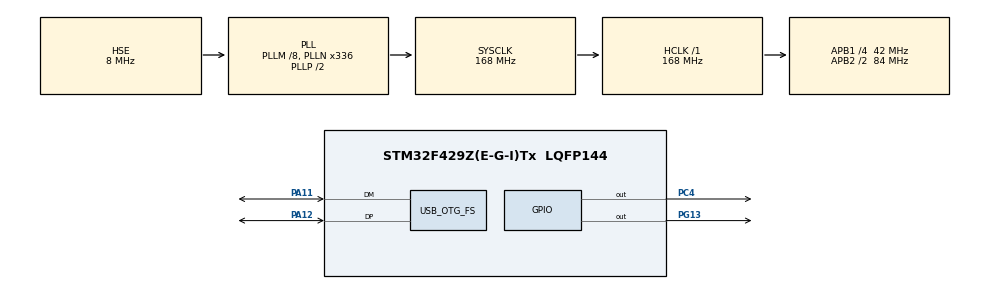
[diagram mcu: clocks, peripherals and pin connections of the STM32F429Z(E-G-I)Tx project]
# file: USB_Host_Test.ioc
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Mcu.Family=STM32F4
Mcu.Name=STM32F429Z(E-G-I)Tx
Mcu.Package=LQFP144
NVIC.OTG_FS_IRQn=true\:0\:0\:false
NVIC.PriorityGroup=NVIC_PRIORITYGROUP_4
PA11.GPIO_Mode=GPIO_MODE_AF_PP
PA11.GPIO_PuPd=GPIO_NOPULL
PA11.GPIO_Speed=GPIO_SPEED_HIGH
PA11.Mode=Host_Only
PA11.Signal=USB_OTG_FS_DM
PA12.GPIO_Mode=GPIO_MODE_AF_PP
PA12.GPIO_PuPd=GPIO_NOPULL
PA12.GPIO_Speed=GPIO_SPEED_HIGH
PA12.Mode=Host_Only
PA12.Signal=USB_OTG_FS_DP
PC4.Signal=GPIO_Output
PG13.Signal=GPIO_Output
PH0/OSC_IN.Mode=HSE-External-Oscillator
PH0/OSC_IN.Signal=RCC_OSC_IN
PH1/OSC_OUT.Mode=HSE-External-Oscillator
PH1/OSC_OUT.Signal=RCC_OSC_OUT
ProjectManager.TargetToolchain=MDK-ARM 4.73
RCC.48MHZClocksFreq_Value=48000000
RCC.AHBFreq_Value=168000000
RCC.APB1CLKDivider=RCC_HCLK_DIV4
RCC.APB1Freq_Value=42000000
RCC.APB1TimFreq_Value=84000000
RCC.APB2CLKDivider=RCC_HCLK_DIV2
RCC.APB2Freq_Value=84000000
RCC.APB2TimFreq_Value=168000000
RCC.CortexFreq_Value=168000000
RCC.HCLKFreq_Value=168000000
RCC.HSE_VALUE=8000000
RCC.HSI_VALUE=16000000
RCC.LSE_VALUE=32768
RCC.PLLM=8
RCC.PLLN=336
RCC.PLLQ=7
RCC.SYSCLKFreq_VALUE=168000000
RCC.SYSCLKSource=RCC_SYSCLKSOURCE_PLLCLK
RCC.VCOOutputFreq_Value=336000000
USB_HOST.BSP.number=1
USB_HOST.USBH_DEBUG_LEVEL-ALL_Classes_FS=3
USB_HOST.USBH_HandleTypeDef-ALL_Classes_FS=hUsbHostFS
USB_HOST.USBH_MAX_DATA_BUFFER-ALL_Classes_FS=4096
USB_HOST.USBH_MAX_NUM_ENDPOINTS-ALL_Classes_FS=1
USB_HOST.USBH_MAX_NUM_SUPPORTED_CLASS-ALL_Classes_FS=6
USB_HOST.USBH_MAX_SIZE_CONFIGURATION-ALL_Classes_FS=512
USB_HOST.VirtualModeFS=All_Classes
USB_HOST.VirtualModeFS-ALL_Classes_FS=All_Classes
USB_HOST0.BSP.i2caddr=0
USB_HOST0.BSP.i2creg=0
USB_HOST0.BSP.instance=PC4
USB_HOST0.BSP.ip=GPIO
USB_HOST0.BSP.mode=Output
USB_HOST0.BSP.name=Drive_VBUS_FS
USB_OTG_FS.phy_itface=HCD_PHY_EMBEDDED
USB_OTG_FS.phy_itface-Host_Only=HCD_PHY_EMBEDDED
VP_USB_HOST_VS_USB_HOST_ALL_CLASS_FS.Mode=ALL_Classes_FS
board=USB_Host_Test

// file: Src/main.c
/**
  ******************************************************************************
  * File Name          : main.c
  * Description        : Main program body
  ******************************************************************************
  *
  * COPYRIGHT(c) 2015 STMicroelectronics
  *
  * Redistribution and use in source and binary forms, with or without modification,
  * are permitted provided that the following conditions are met:
  *   1. Redistributions of source code must retain the above copyright notice,
  *      this list of conditions and the following disclaimer.
  *   2. Redistributions in binary form must reproduce the above copyright notice,
  *      this list of conditions and the following disclaimer in the documentation
  *      and/or other materials provided with the distribution.
  *   3. Neither the name of STMicroelectronics nor the names of its contributors
  *      may be used to endorse or promote products derived from this software
  *      without specific prior written permission.
  *
  * THIS SOFTWARE IS PROVIDED BY THE COPYRIGHT HOLDERS AND CONTRIBUTORS "AS IS"
  * AND ANY EXPRESS OR IMPLIED WARRANTIES, INCLUDING, BUT NOT LIMITED TO, THE
  * IMPLIED WARRANTIES OF MERCHANTABILITY AND FITNESS FOR A PARTICULAR PURPOSE ARE
  * DISCLAIMED. IN NO EVENT SHALL THE COPYRIGHT HOLDER OR CONTRIBUTORS BE LIABLE
  * FOR ANY DIRECT, INDIRECT, INCIDENTAL, SPECIAL, EXEMPLARY, OR CONSEQUENTIAL
  * DAMAGES (INCLUDING, BUT NOT LIMITED TO, PROCUREMENT OF SUBSTITUTE GOODS OR
  * SERVICES; LOSS OF USE, DATA, OR PROFITS; OR BUSINESS INTERRUPTION) HOWEVER
  * CAUSED AND ON ANY THEORY OF LIABILITY, WHETHER IN CONTRACT, STRICT LIABILITY,
  * OR TORT (INCLUDING NEGLIGENCE OR OTHERWISE) ARISING IN ANY WAY OUT OF THE USE
  * OF THIS SOFTWARE, EVEN IF ADVISED OF THE POSSIBILITY OF SUCH DAMAGE.
  *
  ******************************************************************************
  */
#include "stm32f4xx_hal.h"
#include "usb_host.h"

/* USER CODE BEGIN Includes */
#include <stdio.h>

struct __FILE { int handle; /* Add whatever needed */ };
FILE __stdout;
FILE __stdin;

/* USER CODE END Includes */

/* USER CODE BEGIN PV */
/* Private variables ---------------------------------------------------------*/

/* USER CODE END PV */

void SystemClock_Config(void);
static void MX_GPIO_Init(void);
void MX_USB_HOST_Process(void);

/* USER CODE BEGIN PFP */
/* Private function prototypes -----------------------------------------------*/

/* USER CODE END PFP */

int main(void)
{

  /* MCU Configuration----------------------------------------------------------*/

  /* Reset of all peripherals, Initializes the Flash interface and the Systick. */
  HAL_Init();

  /* Configure the system clock */
  SystemClock_Config();

  /* Initialize all configured peripherals */
  MX_GPIO_Init();
  MX_USB_HOST_Init();
	printf("TEST");

  /* Infinite loop */
  while (1)
  {
    MX_USB_HOST_Process();

  }

}

/** System Clock Configuration
*/
void SystemClock_Config(void)
{

  RCC_OscInitTypeDef RCC_OscInitStruct;
  RCC_ClkInitTypeDef RCC_ClkInitStruct;

  __PWR_CLK_ENABLE();

  __HAL_PWR_VOLTAGESCALING_CONFIG(PWR_REGULATOR_VOLTAGE_SCALE1);

  RCC_OscInitStruct.OscillatorType = RCC_OSCILLATORTYPE_HSE;
  RCC_OscInitStruct.HSEState = RCC_HSE_ON;
  RCC_OscInitStruct.PLL.PLLState = RCC_PLL_ON;
  RCC_OscInitStruct.PLL.PLLSource = RCC_PLLSOURCE_HSE;
  RCC_OscInitStruct.PLL.PLLM = 8;
  RCC_OscInitStruct.PLL.PLLN = 336;
  RCC_OscInitStruct.PLL.PLLP = RCC_PLLP_DIV2;
  RCC_OscInitStruct.PLL.PLLQ = 7;
  HAL_RCC_OscConfig(&RCC_OscInitStruct);

  RCC_ClkInitStruct.ClockType = RCC_CLOCKTYPE_SYSCLK|RCC_CLOCKTYPE_PCLK1
                              |RCC_CLOCKTYPE_PCLK2;
  RCC_ClkInitStruct.SYSCLKSource = RCC_SYSCLKSOURCE_PLLCLK;
  RCC_ClkInitStruct.AHBCLKDivider = RCC_SYSCLK_DIV1;
  RCC_ClkInitStruct.APB1CLKDivider = RCC_HCLK_DIV4;
  RCC_ClkInitStruct.APB2CLKDivider = RCC_HCLK_DIV2;
  HAL_RCC_ClockConfig(&RCC_ClkInitStruct, FLASH_LATENCY_5);

  HAL_SYSTICK_Config(HAL_RCC_GetHCLKFreq()/1000);

  HAL_SYSTICK_CLKSourceConfig(SYSTICK_CLKSOURCE_HCLK);

  /* SysTick_IRQn interrupt configuration */
  HAL_NVIC_SetPriority(SysTick_IRQn, 0, 0);
}

/** Configure pins as
        * Analog
        * Input
        * Output
        * EVENT_OUT
        * EXTI
*/
void MX_GPIO_Init(void)
{

  GPIO_InitTypeDef GPIO_InitStruct;

  /* GPIO Ports Clock Enable */
  __GPIOH_CLK_ENABLE();
  __GPIOC_CLK_ENABLE();
  __GPIOA_CLK_ENABLE();
  __GPIOG_CLK_ENABLE();

  /*Configure GPIO pin : PC4 */
  GPIO_InitStruct.Pin = GPIO_PIN_4;
  GPIO_InitStruct.Mode = GPIO_MODE_OUTPUT_PP;
  GPIO_InitStruct.Pull = GPIO_NOPULL;
  GPIO_InitStruct.Speed = GPIO_SPEED_LOW;
  HAL_GPIO_Init(GPIOC, &GPIO_InitStruct);

  /*Configure GPIO pin : PG13 */
  GPIO_InitStruct.Pin = GPIO_PIN_13;
  GPIO_InitStruct.Mode = GPIO_MODE_OUTPUT_PP;
  GPIO_InitStruct.Pull = GPIO_NOPULL;
  GPIO_InitStruct.Speed = GPIO_SPEED_LOW;
  HAL_GPIO_Init(GPIOG, &GPIO_InitStruct);

}

/* USER CODE BEGIN 4 */
int fputc(int ch, FILE *f) {
  return ITM_SendChar(ch);
}
/* USER CODE END 4 */

/************************ (C) COPYRIGHT STMicroelectronics *****END OF FILE****/
